AUTOSAR XML (schema 4-2-2)
package /STELLANTIS/EPT/ASWCs
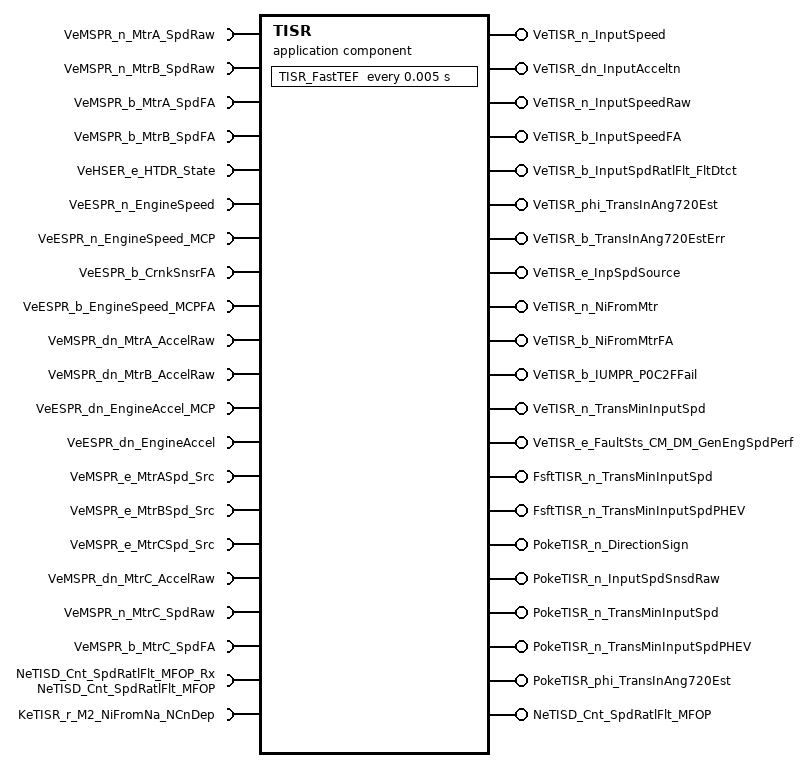
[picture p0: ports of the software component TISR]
  application sw component type TISR
    19 x require port:
      VeMSPR_n_MtrA_SpdRaw: nonqueued-receiver-com-spec{data-element=Value, init-value=0}, required-interface=VeMSPR_n_MtrA_SpdRaw
      VeMSPR_n_MtrB_SpdRaw: nonqueued-receiver-com-spec{data-element=Value, init-value=0}, required-interface=VeMSPR_n_MtrB_SpdRaw
      VeMSPR_b_MtrA_SpdFA: nonqueued-receiver-com-spec{data-element=Value, init-value=0}, required-interface=VeMSPR_b_MtrA_SpdFA
      VeMSPR_b_MtrB_SpdFA: nonqueued-receiver-com-spec{data-element=Value, init-value=0}, required-interface=VeMSPR_b_MtrB_SpdFA
      VeHSER_e_HTDR_State: nonqueued-receiver-com-spec{data-element=Value, init-value=CeHSER_e_Neut_State}, required-interface=VeHSER_e_HTDR_State
      VeESPR_n_EngineSpeed: nonqueued-receiver-com-spec{data-element=Value, init-value=0}, required-interface=VeESPR_n_EngineSpeed
      VeESPR_n_EngineSpeed_MCP: nonqueued-receiver-com-spec{data-element=Value, init-value=0}, required-interface=VeESPR_n_EngineSpeed_MCP
      VeESPR_b_CrnkSnsrFA: nonqueued-receiver-com-spec{data-element=Value, init-value=0}, required-interface=VeESPR_b_CrnkSnsrFA
      VeESPR_b_EngineSpeed_MCPFA: nonqueued-receiver-com-spec{data-element=Value, init-value=0}, required-interface=VeESPR_b_EngineSpeed_MCPFA
      VeMSPR_dn_MtrA_AccelRaw: nonqueued-receiver-com-spec{data-element=Value, init-value=0}, required-interface=VeMSPR_dn_MtrA_AccelRaw
      VeMSPR_dn_MtrB_AccelRaw: nonqueued-receiver-com-spec{data-element=Value, init-value=0}, required-interface=VeMSPR_dn_MtrB_AccelRaw
      VeESPR_dn_EngineAccel_MCP: nonqueued-receiver-com-spec{data-element=Value, init-value=0}, required-interface=VeESPR_dn_EngineAccel_MCP
      VeESPR_dn_EngineAccel: nonqueued-receiver-com-spec{data-element=Value, init-value=0}, required-interface=VeESPR_dn_EngineAccel
      VeMSPR_e_MtrASpd_Src: nonqueued-receiver-com-spec{data-element=Value, init-value=CeMSPR_e_MtrSpSrc_MCP}, required-interface=VeMSPR_e_MtrASpd_Src
      VeMSPR_e_MtrBSpd_Src: nonqueued-receiver-com-spec{data-element=Value, init-value=CeMSPR_e_MtrSpSrc_MCP}, required-interface=VeMSPR_e_MtrBSpd_Src
      VeMSPR_e_MtrCSpd_Src: nonqueued-receiver-com-spec{data-element=Value, init-value=CeMSPR_e_MtrSpSrc_MCP}, required-interface=VeMSPR_e_MtrCSpd_Src
      VeMSPR_dn_MtrC_AccelRaw: nonqueued-receiver-com-spec{data-element=Value, init-value=0}, required-interface=VeMSPR_dn_MtrC_AccelRaw
      VeMSPR_n_MtrC_SpdRaw: nonqueued-receiver-com-spec{data-element=Value, init-value=0}, required-interface=VeMSPR_n_MtrC_SpdRaw
      VeMSPR_b_MtrC_SpdFA: nonqueued-receiver-com-spec{data-element=Value, init-value=0}, required-interface=VeMSPR_b_MtrC_SpdFA
    20 x provide port:
      VeTISR_n_InputSpeed: nonqueued-sender-com-spec{data-element=Value, init-value=0}, provided-interface=VeTISR_n_InputSpeed
      VeTISR_dn_InputAcceltn: nonqueued-sender-com-spec{data-element=Value, init-value=0}, provided-interface=VeTISR_dn_InputAcceltn
      VeTISR_n_InputSpeedRaw: nonqueued-sender-com-spec{data-element=Value, init-value=0}, provided-interface=VeTISR_n_InputSpeedRaw
      VeTISR_b_InputSpeedFA: nonqueued-sender-com-spec{data-element=Value, init-value=0}, provided-interface=VeTISR_b_InputSpeedFA
      VeTISR_b_InputSpdRatlFlt_FltDtct: nonqueued-sender-com-spec{data-element=Value, init-value=0}, provided-interface=VeTISR_b_InputSpdRatlFlt_FltDtct
      VeTISR_phi_TransInAng720Est: nonqueued-sender-com-spec{data-element=Value, init-value=0}, provided-interface=VeTISR_phi_TransInAng720Est
      VeTISR_b_TransInAng720EstErr: nonqueued-sender-com-spec{data-element=Value, init-value=0}, provided-interface=VeTISR_b_TransInAng720EstErr
      VeTISR_e_InpSpdSource: nonqueued-sender-com-spec{data-element=Value, init-value=CeTISR_e_EngSpeedFromCAN}, provided-interface=VeTISR_e_InpSpdSource
      VeTISR_n_NiFromMtr: nonqueued-sender-com-spec{data-element=Value, init-value=0}, provided-interface=VeTISR_n_NiFromMtr
      VeTISR_b_NiFromMtrFA: nonqueued-sender-com-spec{data-element=Value, init-value=0}, provided-interface=VeTISR_b_NiFromMtrFA
      VeTISR_b_IUMPR_P0C2FFail: nonqueued-sender-com-spec{data-element=Value, init-value=0}, provided-interface=VeTISR_b_IUMPR_P0C2FFail
      VeTISR_n_TransMinInputSpd: nonqueued-sender-com-spec{data-element=Value, init-value=0}, provided-interface=VeTISR_n_TransMinInputSpd
      VeTISR_e_FaultSts_CM_DM_GenEngSpdPerf: nonqueued-sender-com-spec{data-element=Value, init-value=CeDFIB_e_Init}, provided-interface=VeTISR_e_FaultSts_CM_DM_GenEngSpdPerf
      FsftTISR_n_TransMinInputSpd: server-com-spec=FsftTISR_n_TransMinInputSpd, provided-interface=FsftTISR_n_TransMinInputSpd
      FsftTISR_n_TransMinInputSpdPHEV: server-com-spec=FsftTISR_n_TransMinInputSpdPHEV, provided-interface=FsftTISR_n_TransMinInputSpdPHEV
      PokeTISR_n_DirectionSign: server-com-spec{operation=PokeTISR_n_DirectionSign, queue-length=1}, provided-interface=PokeTISR_n_DirectionSign
      PokeTISR_n_InputSpdSnsdRaw: server-com-spec{operation=PokeTISR_n_InputSpdSnsdRaw, queue-length=1}, provided-interface=PokeTISR_n_InputSpdSnsdRaw
      PokeTISR_n_TransMinInputSpd: server-com-spec{operation=PokeTISR_n_TransMinInputSpd, queue-length=1}, provided-interface=PokeTISR_n_TransMinInputSpd
      PokeTISR_n_TransMinInputSpdPHEV: server-com-spec{operation=PokeTISR_n_TransMinInputSpdPHEV, queue-length=1}, provided-interface=PokeTISR_n_TransMinInputSpdPHEV
      PokeTISR_phi_TransInAng720Est: server-com-spec{operation=PokeTISR_phi_TransInAng720Est, queue-length=1}, provided-interface=PokeTISR_phi_TransInAng720Est
    require port NeTISD_Cnt_SpdRatlFlt_MFOP_Rx: nv-require-com-spec{init-value=0, variable=NeTISD_Cnt_SpdRatlFlt_MFOP}, required-interface=NeTISD_Cnt_SpdRatlFlt_MFOP
    provide port NeTISD_Cnt_SpdRatlFlt_MFOP: nv-provide-com-spec{ram-block-init-value=0, variable=NeTISD_Cnt_SpdRatlFlt_MFOP}, provided-interface=NeTISD_Cnt_SpdRatlFlt_MFOP
    require port KeTISR_r_M2_NiFromNa_NCnDep: parameter-require-com-spec{init-value=KeTISR_r_M2_NiFromNa_NCnDep_KeTISR_r_M2_NiFromNa_NCnDep:0.24074099957943, parameter=KeTISR_r_M2_NiFromNa_NCnDep}, required-interface=KeTISR_r_M2_NiFromNa_NCnDep
    behavior IB_TISR: data-type-mapping=msADTtoIDTMapping, handle-termination-and-restart=NO-SUPPORT
      timing event Event_FastTEF: start-on-event=TISR_FastTEF, period=0.005
      7 x operation invoked event:
        Event_FsftTISR_n_TransMinInputSpd: start-on-event=FsftTISR_n_TransMinInputSpd, operation=FsftTISR_n_TransMinInputSpd.FsftTISR_n_TransMinInputSpd
        Event_FsftTISR_n_TransMinInputSpdPHEV: start-on-event=FsftTISR_n_TransMinInputSpdPHEV, operation=FsftTISR_n_TransMinInputSpdPHEV.FsftTISR_n_TransMinInputSpdPHEV
        Event_PokeTISR_n_DirectionSign: start-on-event=PokeTISR_n_DirectionSign, operation=PokeTISR_n_DirectionSign.PokeTISR_n_DirectionSign
        Event_PokeTISR_n_InputSpdSnsdRaw: start-on-event=PokeTISR_n_InputSpdSnsdRaw, operation=PokeTISR_n_InputSpdSnsdRaw.PokeTISR_n_InputSpdSnsdRaw
        Event_PokeTISR_n_TransMinInputSpd: start-on-event=PokeTISR_n_TransMinInputSpd, operation=PokeTISR_n_TransMinInputSpd.PokeTISR_n_TransMinInputSpd
        Event_PokeTISR_n_TransMinInputSpdPHEV: start-on-event=PokeTISR_n_TransMinInputSpdPHEV, operation=PokeTISR_n_TransMinInputSpdPHEV.PokeTISR_n_TransMinInputSpdPHEV
        Event_PokeTISR_phi_TransInAng720Est: start-on-event=PokeTISR_phi_TransInAng720Est, operation=PokeTISR_phi_TransInAng720Est.PokeTISR_phi_TransInAng720Est
      init event Event_TISR_ac_Init: start-on-event=TISR_ac_Init
      init event Event_PwrOn: start-on-event=TISR_PwrOn
      init event Event_PwrOff: start-on-event=TISR_PwrOff
      explicit-inter-runnable-variables:
        5 x data, all with category=VALUE, sw-calibration-access=READ-ONLY, init-value=0:
          VeTISR_n_InputSpdSnsdRaw_write_IRV: type=Float
          VeTISR_n_DirectionSign_write_IRV: type=Float
          VeTISR_b_SnsrInputSpdRawFA_write_IRV: type=Boolean
          VeTISR_n_TransMinInputSpd_write_IRV: type=Float
          VeTISR_n_TransMinInputSpdPHEV_write_IRV: type=Float
      11 x runnable:
        TISR_ac_Init
          data-send-points:
            access OUT_VeTISR_e_InpSpdSource_Value: accessed-variable=VeTISR_e_InpSpdSource.Value
            access OUT_VeTISR_e_FaultSts_CM_DM_GenEngSpdPerf_Value: accessed-variable=VeTISR_e_FaultSts_CM_DM_GenEngSpdPerf.Value
        TISR_PwrOn
          data-receive-point-by-arguments:
            access IN_NeTISD_Cnt_SpdRatlFlt_MFOP_Rx_NeTISD_Cnt_SpdRatlFlt_MFOP: accessed-variable=NeTISD_Cnt_SpdRatlFlt_MFOP_Rx.NeTISD_Cnt_SpdRatlFlt_MFOP
          data-send-points:
            13 x access:
              OUT_VeTISR_phi_TransInAng720Est_Value: accessed-variable=VeTISR_phi_TransInAng720Est.Value
              OUT_VeTISR_b_TransInAng720EstErr_Value: accessed-variable=VeTISR_b_TransInAng720EstErr.Value
              OUT_VeTISR_n_InputSpeed_Value: accessed-variable=VeTISR_n_InputSpeed.Value
              OUT_VeTISR_dn_InputAcceltn_Value: accessed-variable=VeTISR_dn_InputAcceltn.Value
              OUT_VeTISR_n_InputSpeedRaw_Value: accessed-variable=VeTISR_n_InputSpeedRaw.Value
              OUT_VeTISR_b_InputSpeedFA_Value: accessed-variable=VeTISR_b_InputSpeedFA.Value
              OUT_VeTISR_n_NiFromMtr_Value: accessed-variable=VeTISR_n_NiFromMtr.Value
              OUT_VeTISR_b_NiFromMtrFA_Value: accessed-variable=VeTISR_b_NiFromMtrFA.Value
              OUT_VeTISR_b_InputSpdRatlFlt_FltDtct_Value: accessed-variable=VeTISR_b_InputSpdRatlFlt_FltDtct.Value
              OUT_VeTISR_e_InpSpdSource_Value: accessed-variable=VeTISR_e_InpSpdSource.Value
              OUT_VeTISR_b_IUMPR_P0C2FFail_Value: accessed-variable=VeTISR_b_IUMPR_P0C2FFail.Value
              OUT_VeTISR_n_TransMinInputSpd_Value: accessed-variable=VeTISR_n_TransMinInputSpd.Value
              OUT_VeTISR_e_FaultSts_CM_DM_GenEngSpdPerf_Value: accessed-variable=VeTISR_e_FaultSts_CM_DM_GenEngSpdPerf.Value
          written-local-variables:
            5 x access:
              WV_VeTISR_n_DirectionSign_write_IRV: accessed-variable=VeTISR_n_DirectionSign_write_IRV
              WV_VeTISR_n_InputSpdSnsdRaw_write_IRV: accessed-variable=VeTISR_n_InputSpdSnsdRaw_write_IRV
              WV_VeTISR_b_SnsrInputSpdRawFA_write_IRV: accessed-variable=VeTISR_b_SnsrInputSpdRawFA_write_IRV
              WV_VeTISR_n_TransMinInputSpdPHEV_write_IRV: accessed-variable=VeTISR_n_TransMinInputSpdPHEV_write_IRV
              WV_VeTISR_n_TransMinInputSpd_write_IRV: accessed-variable=VeTISR_n_TransMinInputSpd_write_IRV
        TISR_FastTEF
          data-receive-point-by-arguments:
            19 x access:
              IN_VeESPR_b_CrnkSnsrFA_Value: accessed-variable=VeESPR_b_CrnkSnsrFA.Value
              IN_VeESPR_b_EngineSpeed_MCPFA_Value: accessed-variable=VeESPR_b_EngineSpeed_MCPFA.Value
              IN_VeESPR_dn_EngineAccel_Value: accessed-variable=VeESPR_dn_EngineAccel.Value
              IN_VeESPR_dn_EngineAccel_MCP_Value: accessed-variable=VeESPR_dn_EngineAccel_MCP.Value
              IN_VeESPR_n_EngineSpeed_Value: accessed-variable=VeESPR_n_EngineSpeed.Value
              IN_VeESPR_n_EngineSpeed_MCP_Value: accessed-variable=VeESPR_n_EngineSpeed_MCP.Value
              IN_VeHSER_e_HTDR_State_Value: accessed-variable=VeHSER_e_HTDR_State.Value
              IN_VeMSPR_b_MtrA_SpdFA_Value: accessed-variable=VeMSPR_b_MtrA_SpdFA.Value
              IN_VeMSPR_b_MtrB_SpdFA_Value: accessed-variable=VeMSPR_b_MtrB_SpdFA.Value
              IN_VeMSPR_b_MtrC_SpdFA_Value: accessed-variable=VeMSPR_b_MtrC_SpdFA.Value
              IN_VeMSPR_dn_MtrA_AccelRaw_Value: accessed-variable=VeMSPR_dn_MtrA_AccelRaw.Value
              IN_VeMSPR_dn_MtrB_AccelRaw_Value: accessed-variable=VeMSPR_dn_MtrB_AccelRaw.Value
              IN_VeMSPR_dn_MtrC_AccelRaw_Value: accessed-variable=VeMSPR_dn_MtrC_AccelRaw.Value
              IN_VeMSPR_e_MtrASpd_Src_Value: accessed-variable=VeMSPR_e_MtrASpd_Src.Value
              IN_VeMSPR_e_MtrBSpd_Src_Value: accessed-variable=VeMSPR_e_MtrBSpd_Src.Value
              IN_VeMSPR_e_MtrCSpd_Src_Value: accessed-variable=VeMSPR_e_MtrCSpd_Src.Value
              IN_VeMSPR_n_MtrA_SpdRaw_Value: accessed-variable=VeMSPR_n_MtrA_SpdRaw.Value
              IN_VeMSPR_n_MtrB_SpdRaw_Value: accessed-variable=VeMSPR_n_MtrB_SpdRaw.Value
              IN_VeMSPR_n_MtrC_SpdRaw_Value: accessed-variable=VeMSPR_n_MtrC_SpdRaw.Value
          data-send-points:
            11 x access:
              OUT_VeTISR_e_InpSpdSource_Value: accessed-variable=VeTISR_e_InpSpdSource.Value
              OUT_VeTISR_b_InputSpdRatlFlt_FltDtct_Value: accessed-variable=VeTISR_b_InputSpdRatlFlt_FltDtct.Value
              OUT_VeTISR_n_InputSpeed_Value: accessed-variable=VeTISR_n_InputSpeed.Value
              OUT_VeTISR_dn_InputAcceltn_Value: accessed-variable=VeTISR_dn_InputAcceltn.Value
              OUT_VeTISR_n_InputSpeedRaw_Value: accessed-variable=VeTISR_n_InputSpeedRaw.Value
              OUT_VeTISR_b_InputSpeedFA_Value: accessed-variable=VeTISR_b_InputSpeedFA.Value
              OUT_VeTISR_n_NiFromMtr_Value: accessed-variable=VeTISR_n_NiFromMtr.Value
              OUT_VeTISR_b_NiFromMtrFA_Value: accessed-variable=VeTISR_b_NiFromMtrFA.Value
              OUT_VeTISR_b_IUMPR_P0C2FFail_Value: accessed-variable=VeTISR_b_IUMPR_P0C2FFail.Value
              OUT_VeTISR_n_TransMinInputSpd_Value: accessed-variable=VeTISR_n_TransMinInputSpd.Value
              OUT_VeTISR_e_FaultSts_CM_DM_GenEngSpdPerf_Value: accessed-variable=VeTISR_e_FaultSts_CM_DM_GenEngSpdPerf.Value
          parameter access CALPRM_KeTISR_r_M2_NiFromNa_NCnDep_KeTISR_r_M2_NiFromNa_NCnDep: accessed-parameter=KeTISR_r_M2_NiFromNa_NCnDep.KeTISR_r_M2_NiFromNa_NCnDep
          read-local-variables:
            5 x access:
              RV_VeTISR_b_SnsrInputSpdRawFA_write_IRV: accessed-variable=VeTISR_b_SnsrInputSpdRawFA_write_IRV
              RV_VeTISR_n_DirectionSign_write_IRV: accessed-variable=VeTISR_n_DirectionSign_write_IRV
              RV_VeTISR_n_InputSpdSnsdRaw_write_IRV: accessed-variable=VeTISR_n_InputSpdSnsdRaw_write_IRV
              RV_VeTISR_n_TransMinInputSpdPHEV_write_IRV: accessed-variable=VeTISR_n_TransMinInputSpdPHEV_write_IRV
              RV_VeTISR_n_TransMinInputSpd_write_IRV: accessed-variable=VeTISR_n_TransMinInputSpd_write_IRV
        TISR_PwrOff
          data-send-points:
            access OUT_NeTISD_Cnt_SpdRatlFlt_MFOP_NeTISD_Cnt_SpdRatlFlt_MFOP: accessed-variable=NeTISD_Cnt_SpdRatlFlt_MFOP.NeTISD_Cnt_SpdRatlFlt_MFOP
        FsftTISR_n_TransMinInputSpd
          written-local-variables:
            access WV_VeTISR_n_TransMinInputSpd_write_IRV: accessed-variable=VeTISR_n_TransMinInputSpd_write_IRV
        FsftTISR_n_TransMinInputSpdPHEV
          written-local-variables:
            access WV_VeTISR_n_TransMinInputSpdPHEV_write_IRV: accessed-variable=VeTISR_n_TransMinInputSpdPHEV_write_IRV
        PokeTISR_n_DirectionSign
          written-local-variables:
            access WV_VeTISR_n_DirectionSign_write_IRV: accessed-variable=VeTISR_n_DirectionSign_write_IRV
        PokeTISR_n_InputSpdSnsdRaw
          written-local-variables:
            access WV_VeTISR_b_SnsrInputSpdRawFA_write_IRV: accessed-variable=VeTISR_b_SnsrInputSpdRawFA_write_IRV
            access WV_VeTISR_n_InputSpdSnsdRaw_write_IRV: accessed-variable=VeTISR_n_InputSpdSnsdRaw_write_IRV
        PokeTISR_n_TransMinInputSpd
          written-local-variables:
            access WV_VeTISR_n_TransMinInputSpd_write_IRV: accessed-variable=VeTISR_n_TransMinInputSpd_write_IRV
        PokeTISR_n_TransMinInputSpdPHEV
          written-local-variables:
            access WV_VeTISR_n_TransMinInputSpdPHEV_write_IRV: accessed-variable=VeTISR_n_TransMinInputSpdPHEV_write_IRV
        PokeTISR_phi_TransInAng720Est
          data-send-points:
            access OUT_VeTISR_phi_TransInAng720Est_Value: accessed-variable=VeTISR_phi_TransInAng720Est.Value
            access OUT_VeTISR_b_TransInAng720EstErr_Value: accessed-variable=VeTISR_b_TransInAng720EstErr.Value
      variation point proxy Variant_TISR_1: category=CONDITION, condition-access=0
      variation point proxy Variant_TISR_3: category=CONDITION, condition-access=1
